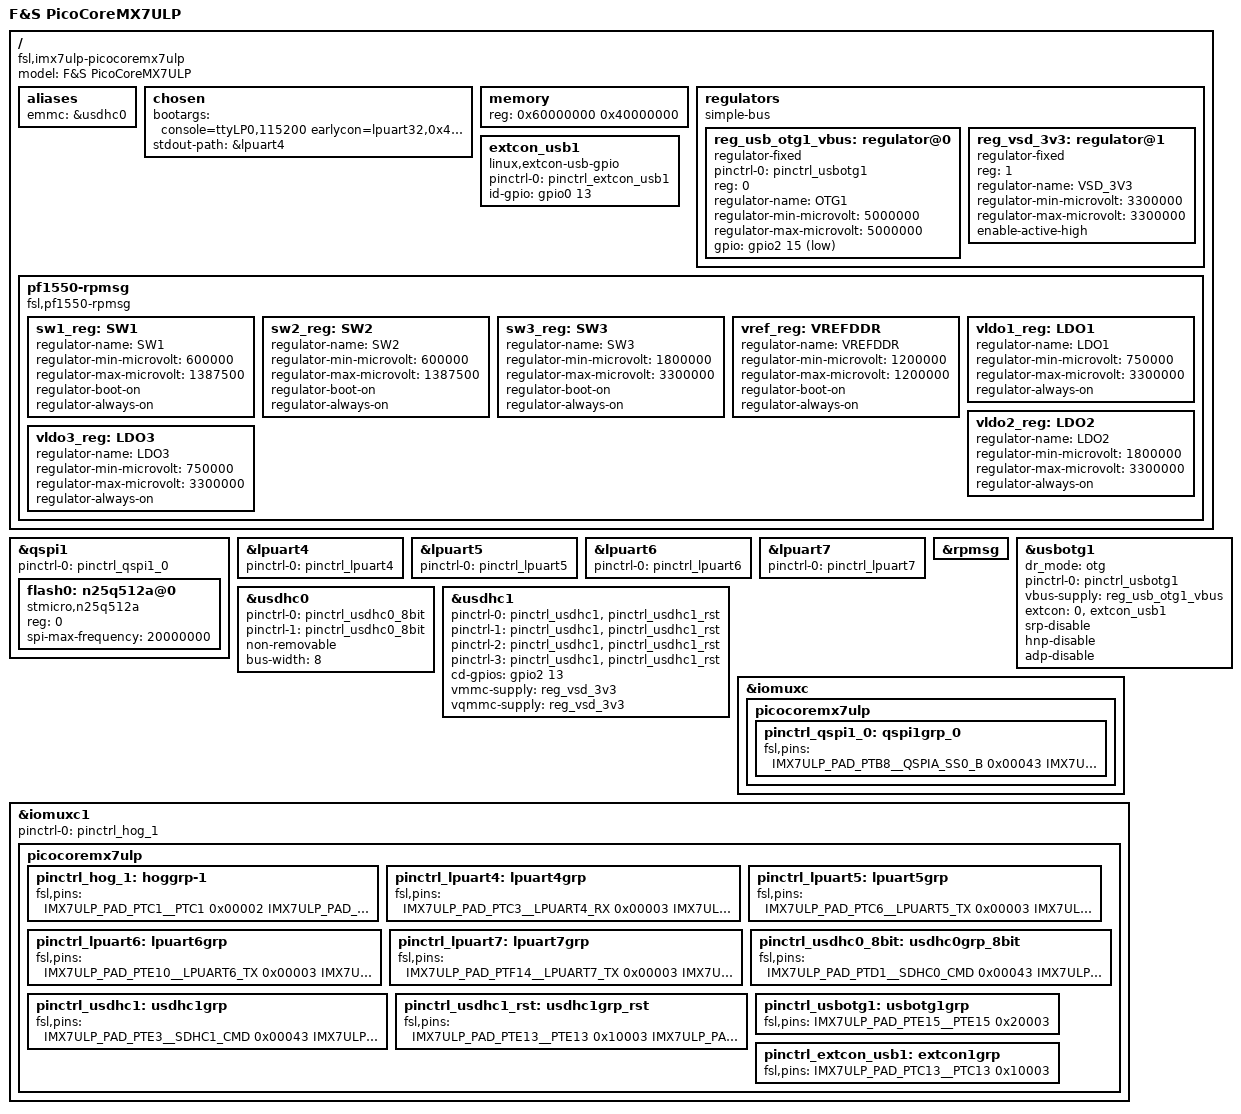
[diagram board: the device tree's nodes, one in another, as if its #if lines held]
/*
* Copyright 2019-2022 F&S Elektronik Systeme GmbH
*
* This program is free software; you can redistribute it and/or
* modify it under the terms of the GNU General Public License
* as published by the Free Software Foundation; either version 2
* of the License, or (at your option) any later version.
*
* This program is distributed in the hope that it will be useful,
* but WITHOUT ANY WARRANTY; without even the implied warranty of
* MERCHANTABILITY or FITNESS FOR A PARTICULAR PURPOSE.  See the
* GNU General Public License for more details.
*
*/

/dts-v1/;

/* Set board revision as 3-digit number, e.g. 120 for board rev. 1.20 */
#define CONFIG_PICOCOREMX7ULP_BOARD_REVISION	120

/* SD card */
/* default WIFI */
//#define CONFIG_PICOCOREMX7ULP_SD

#include "imx7ulp.dtsi"

/ {
	model = "F&S PicoCoreMX7ULP";
	compatible = "fsl,imx7ulp-picocoremx7ulp", "fsl,imx7ulp", "Generic DT based system";

	aliases {
		emmc = &usdhc0;
	};

	chosen {
		bootargs = "console=ttyLP0,115200 earlycon=lpuart32,0x402D0010,115200";
		stdout-path = &lpuart4;
	};

	memory {
		device_type = "memory";
		reg = <0x60000000 0x40000000>;
	};

	regulators {
		compatible = "simple-bus";
		#address-cells = <1>;
		#size-cells = <0>;

		reg_usb_otg1_vbus: regulator@0 {
			pinctrl-names = "default";
			pinctrl-0 = <&pinctrl_usbotg1>;
			compatible = "regulator-fixed";
			reg = <0>;
			regulator-name = "OTG1";
			regulator-min-microvolt = <5000000>;
			regulator-max-microvolt = <5000000>;
			gpio = <&gpio2 15 GPIO_ACTIVE_LOW>;
		};

		reg_vsd_3v3: regulator@1 {
			compatible = "regulator-fixed";
			reg = <1>;
			regulator-name = "VSD_3V3";
			regulator-min-microvolt = <3300000>;
			regulator-max-microvolt = <3300000>;
			enable-active-high;
		};
	};

	extcon_usb1: extcon_usb1 {
		compatible = "linux,extcon-usb-gpio";
		pinctrl-names = "default";
		pinctrl-0 = <&pinctrl_extcon_usb1>;
		id-gpio = <&gpio0 13 GPIO_ACTIVE_HIGH>;
	};

	pf1550-rpmsg {
		compatible = "fsl,pf1550-rpmsg";
		sw1_reg: SW1 {
				regulator-name = "SW1";
				regulator-min-microvolt = <600000>;
				regulator-max-microvolt = <1387500>;
				regulator-boot-on;
				regulator-always-on;
		};

		sw2_reg: SW2 {
				regulator-name = "SW2";
				regulator-min-microvolt = <600000>;
				regulator-max-microvolt = <1387500>;
				regulator-boot-on;
				regulator-always-on;
		};

		sw3_reg: SW3 {
				regulator-name = "SW3";
				regulator-min-microvolt = <1800000>;
				regulator-max-microvolt = <3300000>;
				regulator-boot-on;
				regulator-always-on;
		};

		vref_reg: VREFDDR {
				regulator-name = "VREFDDR";
				regulator-min-microvolt = <1200000>;
				regulator-max-microvolt = <1200000>;
				regulator-boot-on;
				regulator-always-on;
		};

		vldo1_reg: LDO1 {
				regulator-name = "LDO1";
				regulator-min-microvolt = <750000>;
				regulator-max-microvolt = <3300000>;
				regulator-always-on;
		};

		vldo2_reg: LDO2 {
				regulator-name = "LDO2";
				regulator-min-microvolt = <1800000>;
				regulator-max-microvolt = <3300000>;
				regulator-always-on;
		};

		vldo3_reg: LDO3 {
				regulator-name = "LDO3";
				regulator-min-microvolt = <750000>;
				regulator-max-microvolt = <3300000>;
				regulator-always-on;
		};
	};
};

&qspi1 {
	pinctrl-names = "default";
	pinctrl-0 = <&pinctrl_qspi1_0>;
	status = "okay";

	flash0: n25q512a@0 {
		reg = <0>;
		#address-cells = <1>;
		#size-cells = <1>;
		compatible = "stmicro,n25q512a";
		spi-max-frequency = <20000000>;
	};
};

&lpuart4 {
	pinctrl-names = "default";
	pinctrl-0 = <&pinctrl_lpuart4>;
	status = "okay";
};

&lpuart5 {
	pinctrl-names = "default";
	pinctrl-0 = <&pinctrl_lpuart5>;
	status = "okay";
};


&lpuart6 {
	pinctrl-names = "default";
	pinctrl-0 = <&pinctrl_lpuart6>;
	status = "okay";
};

&lpuart7 {
	pinctrl-names = "default";
	pinctrl-0 = <&pinctrl_lpuart7>;
	status = "okay";
};

&rpmsg{
	status = "okay";
};

&usbotg1 {
	dr_mode = "otg";
	pinctrl-names = "default";
	pinctrl-0 = <&pinctrl_usbotg1>;
	vbus-supply = <&reg_usb_otg1_vbus>;
	extcon = <0>, <&extcon_usb1>;
	srp-disable;
	hnp-disable;
	adp-disable;
	status = "okay";
};

&usdhc0 {
	pinctrl-names = "default", "sleep";
	pinctrl-0 = <&pinctrl_usdhc0_8bit>;
	pinctrl-1 = <&pinctrl_usdhc0_8bit>;
	non-removable;
	bus-width = <8>;
	status = "okay";
};

#ifdef CONFIG_PICOCOREMX7ULP_SD
&usdhc1 {
	pinctrl-names = "default", "state_100mhz", "state_200mhz", "sleep";
	pinctrl-0 = <&pinctrl_usdhc1 &pinctrl_usdhc1_rst>;
	pinctrl-1 = <&pinctrl_usdhc1 &pinctrl_usdhc1_rst>;
	pinctrl-2 = <&pinctrl_usdhc1 &pinctrl_usdhc1_rst>;
	pinctrl-3 = <&pinctrl_usdhc1 &pinctrl_usdhc1_rst>;
	cd-gpios = <&gpio2 13 GPIO_ACTIVE_HIGH>;
	vmmc-supply = <&reg_vsd_3v3>;
	vqmmc-supply = <&reg_vsd_3v3>;
	status = "okay";
};
#endif

&iomuxc {
	status = "okay";

	picocoremx7ulp {

		pinctrl_qspi1_0: qspi1grp_0 {
			fsl,pins = <
				IMX7ULP_PAD_PTB8__QSPIA_SS0_B	0x00043 /* SS0 */
				IMX7ULP_PAD_PTB15__QSPIA_SCLK	0x00043 /* SCLK */
				IMX7ULP_PAD_PTB16__QSPIA_DATA3	0x00043 /* D3 */
				IMX7ULP_PAD_PTB17__QSPIA_DATA2	0x00043 /* D2 */
				IMX7ULP_PAD_PTB18__QSPIA_DATA1	0x00043 /* D1 */
				IMX7ULP_PAD_PTB19__QSPIA_DATA0	0x00043 /* D0 */
			>;
		};
	};
};

&iomuxc1 {
	pinctrl-names = "default";
	pinctrl-0 = <&pinctrl_hog_1>;
	status = "okay";

	picocoremx7ulp {
		pinctrl_hog_1: hoggrp-1 {
			fsl,pins = <
				/* TP 5 */
				IMX7ULP_PAD_PTC1__PTC1		0x00002
				/* USHC1_VSEL */
				IMX7ULP_PAD_PTE14__SDHC1_VS	0x00043
			>;
		};

		pinctrl_lpuart4: lpuart4grp {
			fsl,pins = <
				IMX7ULP_PAD_PTC3__LPUART4_RX	0x00003
				IMX7ULP_PAD_PTC2__LPUART4_TX	0x00003

			>;
		};

		pinctrl_lpuart5: lpuart5grp {
			fsl,pins = <
				IMX7ULP_PAD_PTC6__LPUART5_TX	0x00003
				IMX7ULP_PAD_PTC7__LPUART5_RX	0x00003

			>;
		};

		pinctrl_lpuart6: lpuart6grp {
			fsl,pins = <
				IMX7ULP_PAD_PTE10__LPUART6_TX	0x00003
				IMX7ULP_PAD_PTE11__LPUART6_RX	0x00003
				IMX7ULP_PAD_PTE8__LPUART6_CTS_B	0x00003
				IMX7ULP_PAD_PTE9__LPUART6_RTS_B	0x00003

			>;
		};

		pinctrl_lpuart7: lpuart7grp {
			fsl,pins = <
				IMX7ULP_PAD_PTF14__LPUART7_TX	0x00003
				IMX7ULP_PAD_PTF15__LPUART7_RX	0x00003

			>;
		};

		/* eMMC */
		pinctrl_usdhc0_8bit: usdhc0grp_8bit {
			fsl,pins = <
				IMX7ULP_PAD_PTD1__SDHC0_CMD	0x00043
				IMX7ULP_PAD_PTD2__SDHC0_CLK	0x00043
				IMX7ULP_PAD_PTD3__SDHC0_D7	0x00043
				IMX7ULP_PAD_PTD4__SDHC0_D6	0x00043
				IMX7ULP_PAD_PTD5__SDHC0_D5	0x00043
				IMX7ULP_PAD_PTD6__SDHC0_D4	0x00043
				IMX7ULP_PAD_PTD7__SDHC0_D3	0x00043
				IMX7ULP_PAD_PTD8__SDHC0_D2	0x00043
				IMX7ULP_PAD_PTD9__SDHC0_D1	0x00043
				IMX7ULP_PAD_PTD10__SDHC0_D0	0x00043
				/* CD pin - n.c. */
				IMX7ULP_PAD_PTC10__PTC10	0x10002
				/* nRST */
				IMX7ULP_PAD_PTD0__PTD0		0x00003
			>;
		};
#ifdef CONFIG_PICOCOREMX7ULP_SD
		/* MICRO-SD */
		pinctrl_usdhc1: usdhc1grp {
			fsl,pins = <
				IMX7ULP_PAD_PTE3__SDHC1_CMD	0x00043
				IMX7ULP_PAD_PTE2__SDHC1_CLK	0x00043
				IMX7ULP_PAD_PTE1__SDHC1_D0	0x00043
				IMX7ULP_PAD_PTE0__SDHC1_D1	0x00043
				IMX7ULP_PAD_PTE5__SDHC1_D2	0x00043
				IMX7ULP_PAD_PTE4__SDHC1_D3	0x00043
			>;
		};

		pinctrl_usdhc1_rst: usdhc1grp_rst {
			fsl,pins = <
				/* USDHC1 CD */
				IMX7ULP_PAD_PTE13__PTE13	0x10003
				/* USDHC1 WP */
				IMX7ULP_PAD_PTE12__PTE12	0x10003
			>;
		};
#endif
		pinctrl_usbotg1: usbotg1grp {
			fsl,pins = <
				/* USB otg Power enable */
				IMX7ULP_PAD_PTE15__PTE15	0x20003
			>;
		};

		pinctrl_extcon_usb1: extcon1grp {
			fsl,pins = <
				IMX7ULP_PAD_PTC13__PTC13	0x10003
			>;
		};
	};
};
